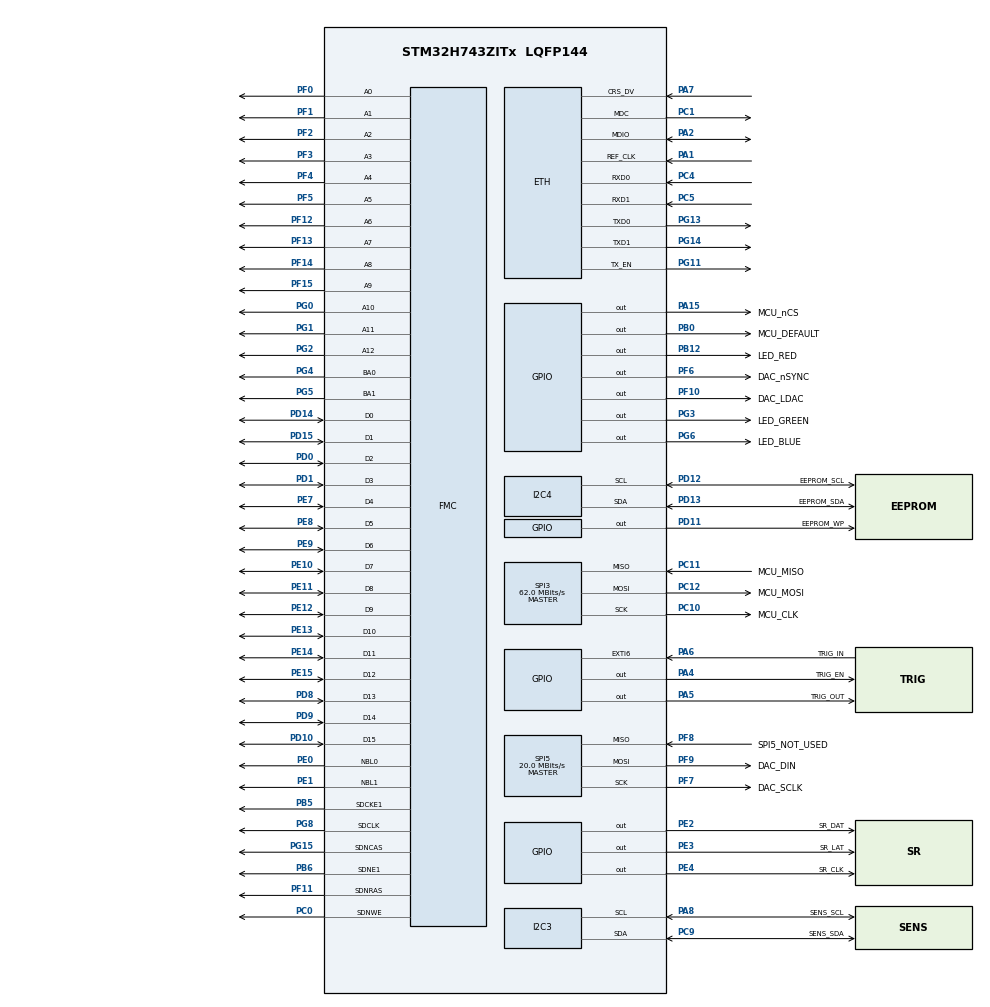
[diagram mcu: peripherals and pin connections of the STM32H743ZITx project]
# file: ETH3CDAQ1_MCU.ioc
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SH.FMC_D7_DA7.0=FMC_D7,sd-16b-d2
FREERTOS.Queues01=QueueTrigger,1,uint8_t,0,Static,QueueTriggerBuffer,QueueTriggerControlBlock
PD12.GPIO_Label=EEPROM_SCL
FMC.RCDDelay2=3
SPI3.Direction=SPI_DIRECTION_2LINES
PG6.PinState=GPIO_PIN_SET
PC10.GPIO_PuPd=GPIO_NOPULL
FMC.SDClockPeriod2=FMC_SDRAM_CLOCK_PERIOD_3
SPI3.VirtualType=VM_MASTER
FMC.SDClockPeriod1=FMC_SDRAM_CLOCK_PERIOD_3
SH.FMC_A0.0=FMC_A0,13b-sda2
PG4.Signal=FMC_A14_BA0
PG8.Signal=FMC_SDCLK
PC12.Signal=SPI3_MOSI
PG6.GPIO_Label=LED_BLUE
PG0.Signal=FMC_A10
CORTEX_M7.TypeExtField-Cortex_Memory_Protection_Unit_Region0_Settings=MPU_TEX_LEVEL1
RCC.PLLFRACN=0
SPI5.DataSize=SPI_DATASIZE_8BIT
FMC.LoadToActiveDelay2=2
PA6.GPIO_Label=TRIG_IN
PA15\ (JTDI).Signal=GPIO_Output
PC5.Mode=RMII
SH.FMC_D5_DA5.0=FMC_D5,sd-16b-d2
PF10.GPIO_PuPd=GPIO_NOPULL
PG13.Signal=ETH_TXD0
PF6.GPIO_Label=DAC_nSYNC
RCC.SYSCLKSource=RCC_SYSCLKSOURCE_PLLCLK
SH.FMC_A15_BA1.0=FMC_BA1,FourSdramBanks2
LWIP.NETMASK_ADDRESS=255.255.255.000
RCC.SPI123CLockSelection=RCC_SPI123CLKSOURCE_PLL2
SH.FMC_D9_DA9.0=FMC_D9,sd-16b-d2
CORTEX_M7.Enable-Cortex_Memory_Protection_Unit_Region0_Settings=MPU_REGION_ENABLE
CORTEX_M7.IsBufferable-Cortex_Memory_Protection_Unit_Region1_Settings=MPU_ACCESS_BUFFERABLE
PF7.Signal=SPI5_SCK
SH.FMC_SDNWE.0=FMC_SDNWE,13b-sda2
I2C4.Timing=0x307075B1
SH.FMC_D11_DA11.0=FMC_D11,sd-16b-d2
PB6.Signal=FMC_SDNE1
PB12.PinState=GPIO_PIN_SET
PB6.Mode=SdramChipSelect2_2
PD0.Signal=FMC_D2_DA2
PD8.Signal=FMC_D13_DA13
PE1.Signal=FMC_NBL1
PF10.GPIO_Label=DAC_LDAC
RCC.DIVM3=4
RCC.DIVM2=4
RCC.DIVM1=4
PB12.GPIO_Label=LED_RED
PG14.Mode=RMII
FMC.SelfRefreshTime2=7
LWIP.MEM_SIZE=16360
PE9.Signal=FMC_D6_DA6
SH.FMC_A2.0=FMC_A2,13b-sda2
PE4.GPIO_Label=SR_CLK
PC9.Mode=I2C
PC11.GPIO_Speed=GPIO_SPEED_FREQ_HIGH
PE2.Signal=GPIO_Output
PF8.Mode=Full_Duplex_Master
PA8.Signal=I2C3_SCL
SH.FMC_D1_DA1.0=FMC_D1,sd-16b-d2
PF3.Signal=FMC_A3
PE10.Signal=FMC_D7_DA7
CORTEX_M7.DisableExec-Cortex_Memory_Protection_Unit_Region1_Settings=MPU_INSTRUCTION_ACCESS_DISABLE
Mcu.Package=LQFP144
NVIC.TimeBase=TIM1_UP_IRQn
SPI3.Mode=SPI_MODE_MASTER
PD12.Signal=I2C4_SCL
NVIC.TimeBaseIP=TIM1
PC11.Mode=Full_Duplex_Master
FMC.WriteRecoveryTime2=4
SH.FMC_A1.0=FMC_A1,13b-sda2
SPI5.CalculateBaudRate=20.0 MBits/s
SH.FMC_SDCLK.0=FMC_SDCLK,13b-sda2
RCC.APB4Freq_Value=120000000
PF14.Signal=FMC_A8
CORTEX_M7.Enable-Cortex_Memory_Protection_Unit_Region1_Settings=MPU_REGION_ENABLE
FREERTOS.configGENERATE_RUN_TIME_STATS=1
FMC.RowCycleDelay2=10
FMC.RowCycleDelay1=10
PH0-OSC_IN\ (PH0).Mode=HSE-External-Oscillator
PA4.GPIO_Label=TRIG_EN
PD15.Signal=FMC_D1_DA1
SH.FMC_D3_DA3.0=FMC_D3,sd-16b-d2
SPI5.VirtualType=VM_MASTER
PC4.Mode=RMII
LWIP.IP_ADDRESS=192.168.000.123
SH.FMC_A4.0=FMC_A4,13b-sda2
RCC.DIVQ1=6
FREERTOS.Tasks01=defaultTask,24,128,StartDefaultTask,Default,NULL,Dynamic,NULL,NULL;LEDTask,8,128,StartTaskLEDStatus,Default,NULL,Dynamic,NULL,NULL;TriggerTask,40,128,StartTriggerTask,Default,NULL,Dynamic,NULL,NULL
LWIP0.BSP.i2caddr=0
PG5.Signal=FMC_A15_BA1
SH.FMC_D10_DA10.0=FMC_D10,sd-16b-d2
PD1.Signal=FMC_D3_DA3
LWIP.LWIP_DHCP=0
PC0.Signal=FMC_SDNWE
LWIP.DEFAULT_THREAD_STACKSIZE=2048
PF8.GPIO_Label=SPI5_NOT_USED
PD10.Signal=FMC_D15_DA15
SH.FMC_A3.0=FMC_A3,13b-sda2
PC10.GPIO_Mode=GPIO_MODE_AF_PP
PA8.GPIO_Label=SENS_SCL
FMC.CASLatency2=FMC_SDRAM_CAS_LATENCY_3
SH.FMC_D15_DA15.0=FMC_D15,sd-16b-d2
RCC.DIVN3=80
RCC.DIVN2=124
RCC.DIVN1=480
CORTEX_M7.BaseAddress-Cortex_Memory_Protection_Unit_Region0_Settings=0x30040000
PA5.Signal=GPIO_Output
PC12.Mode=Full_Duplex_Master
PA15\ (JTDI).GPIO_Speed=GPIO_SPEED_FREQ_VERY_HIGH
PA7.GPIO_Speed=GPIO_SPEED_FREQ_VERY_HIGH
FMC.ReadBurst1=FMC_SDRAM_RBURST_ENABLE
SH.FMC_A6.0=FMC_A6,13b-sda2
FMC.ReadBurst2=FMC_SDRAM_RBURST_ENABLE
PA1.Mode=RMII
PE14.Signal=FMC_D11_DA11
PE15.Signal=FMC_D12_DA12
PE8.Signal=FMC_D5_DA5
RCC.FMCCLockSelection=RCC_FMCCLKSOURCE_PLL
CORTEX_M7.AccessPermission-Cortex_Memory_Protection_Unit_Region0_Settings=MPU_REGION_FULL_ACCESS
PA15\ (JTDI).GPIO_PuPd=GPIO_PULLUP
PF13.Signal=FMC_A7
SH.FMC_SDNCAS.0=FMC_SDNCAS,13b-sda2
PA4.Signal=GPIO_Output
PB5.Signal=FMC_SDCKE1
ETH.MediaInterface=HAL_ETH_RMII_MODE
RCC.Spi45ClockSelection=RCC_SPI45CLKSOURCE_PLL3
PD12.Mode=I2C
PA5.GPIO_Label=TRIG_OUT
PE3.GPIO_Speed=GPIO_SPEED_FREQ_HIGH
PD11.Signal=GPIO_Output
PC12.GPIO_Label=MCU_MOSI
SH.FMC_A5.0=FMC_A5,13b-sda2
PG11.Mode=RMII
ProjectManager.HeapSize=0x200
LWIP.Version=v2.1.2_Cube
PF9.Signal=SPI5_MOSI
NVIC.PriorityGroup=NVIC_PRIORITYGROUP_4
PC5.GPIO_Speed=GPIO_SPEED_FREQ_VERY_HIGH
PF6.GPIO_PuPd=GPIO_PULLUP
PE3.Signal=GPIO_Output
PA8.Mode=I2C
PA15\ (JTDI).PinState=GPIO_PIN_SET
PF4.Signal=FMC_A4
PG3.GPIO_Label=LED_GREEN
PF10.PinState=GPIO_PIN_RESET
PB0.Signal=GPIO_Output
PC1.Signal=ETH_MDC
PC1.Mode=RMII
PF6.GPIO_Speed=GPIO_SPEED_FREQ_HIGH
Mcu.Family=STM32H7
LWIP0.BSP.STBoard=false
SH.FMC_A8.0=FMC_A8,13b-sda2
RCC.CortexFreq_Value=480000000
PG6.Signal=GPIO_Output
RCC.HPRE=RCC_HCLK_DIV2
SH.FMC_D14_DA14.0=FMC_D14,sd-16b-d2
PG2.Signal=FMC_A12
PH0-OSC_IN\ (PH0).Signal=RCC_OSC_IN
PC10.Signal=SPI3_SCK
SH.FMC_NBL0.0=FMC_NBL0,Sd2ByteEnable2
PA2.GPIO_Speed=GPIO_SPEED_FREQ_VERY_HIGH
PE2.GPIO_Speed=GPIO_SPEED_FREQ_HIGH
SH.FMC_D6_DA6.0=FMC_D6,sd-16b-d2
PF9.GPIO_Speed=GPIO_SPEED_FREQ_HIGH
PB0.GPIO_Label=MCU_DEFAULT
PC10.GPIO_Speed=GPIO_SPEED_FREQ_HIGH
NVIC.TIM1_UP_IRQn=true\:0\:0\:false\:false\:true\:false\:false\:true
SH.FMC_A14_BA0.0=FMC_BA0,FourSdramBanks2
SH.FMC_A11.0=FMC_A11,13b-sda2
PG11.Signal=ETH_TX_EN
PG15.Signal=FMC_SDNCAS
ProjectManager.StackSize=0x400
VP_FREERTOS_VS_CMSIS_V2.Mode=CMSIS_V2
PD13.Signal=I2C4_SDA
SH.FMC_A7.0=FMC_A7,13b-sda2
PF6.PinState=GPIO_PIN_SET
PD11.GPIO_Label=EEPROM_WP
FMC.BankMapConfig=FMC_SWAPBMAP_DISABLE
RCC.HCLKFreq_Value=240000000
SH.FMC_NBL1.0=FMC_NBL1,Sd2ByteEnable2
PF12.Signal=FMC_A6
SPI5.CLKPolarity=SPI_POLARITY_HIGH
SH.FMC_A10.0=FMC_A10,13b-sda2
SPI3.DataSize=SPI_DATASIZE_8BIT
NVIC.ETH_IRQn=true\:5\:0\:true\:false\:true\:true\:true\:true
PH1-OSC_OUT\ (PH1).Mode=HSE-External-Oscillator
RCC.HSE_VALUE=8000000
SH.FMC_D8_DA8.0=FMC_D8,sd-16b-d2
FMC.RPDelay2=3
FMC.RPDelay1=3
FMC.ExitSelfRefreshDelay2=11
PA4.GPIO_Speed=GPIO_SPEED_FREQ_MEDIUM
SH.FMC_D2_DA2.0=FMC_D2,sd-16b-d2
PG11.GPIO_Speed=GPIO_SPEED_FREQ_VERY_HIGH
PC4.GPIO_Speed=GPIO_SPEED_FREQ_VERY_HIGH
PF9.Mode=Full_Duplex_Master
PE13.Signal=FMC_D10_DA10
PF7.GPIO_Speed=GPIO_SPEED_FREQ_HIGH
PF7.GPIO_Label=DAC_SCLK
PE4.GPIO_Speed=GPIO_SPEED_FREQ_HIGH
VP_SYS_VS_tim1.Mode=TIM1
PF11.Signal=FMC_SDNRAS
PC11.GPIO_Label=MCU_MISO
PB5.Mode=SdramChipSelect2_2
PG13.Mode=RMII
SH.FMC_SDNRAS.0=FMC_SDNRAS,13b-sda2
LWIP0.BSP.solution=LAN8742
PE4.Signal=GPIO_Output
CORTEX_M7.DisableExec-Cortex_Memory_Protection_Unit_Region0_Settings=MPU_INSTRUCTION_ACCESS_DISABLE
RCC.APB3Freq_Value=120000000
LWIP0.BSP.component=LAN8742
PD13.GPIO_Label=EEPROM_SDA
SPI5.BaudRatePrescaler=SPI_BAUDRATEPRESCALER_4
PA6.Signal=GPXTI6
SH.FMC_D0_DA0.0=FMC_D0,sd-16b-d2
RCC.D1PPRE=RCC_APB3_DIV2
CORTEX_M7.BaseAddress-Cortex_Memory_Protection_Unit_Region1_Settings=0x30040000
SH.FMC_A9.0=FMC_A9,13b-sda2
PF8.Signal=SPI5_MISO
SH.FMC_D4_DA4.0=FMC_D4,sd-16b-d2
PF5.Signal=FMC_A5
CORTEX_M7.Size-Cortex_Memory_Protection_Unit_Region1_Settings=MPU_REGION_SIZE_256B
I2C3.Timing=0x307075B1
PG13.GPIO_Speed=GPIO_SPEED_FREQ_VERY_HIGH
PF0.Signal=FMC_A0
PC5.Signal=ETH_RXD1
PE7.Signal=FMC_D4_DA4
CORTEX_M7.IsShareable-Cortex_Memory_Protection_Unit_Region1_Settings=MPU_ACCESS_SHAREABLE
PE2.GPIO_Label=SR_DAT
SH.FMC_A12.0=FMC_A12,13b-sda2
RCC.PLLSourceVirtual=RCC_PLLSOURCE_HSE
CORTEX_M7.CPU_ICache=Enabled
PA7.Mode=RMII
PC10.GPIO_Label=MCU_CLK
PC9.GPIO_Label=SENS_SDA
PG3.Signal=GPIO_Output
PG1.Signal=FMC_A11
PC11.Signal=SPI3_MISO
PF10.GPIO_Speed=GPIO_SPEED_FREQ_HIGH
PC4.Signal=ETH_RXD0
PC10.Mode=Full_Duplex_Master
LWIP.LWIP_IPV6=0
RCC.D2PPRE2=RCC_APB2_DIV2
RCC.D2PPRE1=RCC_APB1_DIV2
PD9.Signal=FMC_D14_DA14
SPI5.Mode=SPI_MODE_MASTER
PH1-OSC_OUT\ (PH1).Signal=RCC_OSC_OUT
VP_LWIP_VS_Enabled.Mode=Enabled
LWIP.GATEWAY_ADDRESS=192.168.000.001
PB0.GPIO_Speed=GPIO_SPEED_FREQ_HIGH
PF7.Mode=Full_Duplex_Master
CORTEX_M7.MPU_Control=MPU_PRIVILEGED_DEFAULT
PA4.PinState=GPIO_PIN_SET
PF6.Signal=GPIO_Output
ProjectManager.TargetToolchain=STM32CubeIDE
SH.FMC_D13_DA13.0=FMC_D13,sd-16b-d2
LWIP.TCPIP_THREAD_STACKSIZE=2048
PD13.Mode=I2C
PF2.Signal=FMC_A2
LWIP0.BSP.instance=LAN8742
RCC.USBFreq_Value=160000000
PF9.GPIO_Label=DAC_DIN
PE11.Signal=FMC_D8_DA8
LWIP0.BSP.api=BSP_COMPONENT_DRIVER
PA1.Signal=ETH_REF_CLK
PG14.Signal=ETH_TXD1
board=custom
PG3.PinState=GPIO_PIN_SET
RCC.APB2Freq_Value=120000000
SPI3.CalculateBaudRate=62.0 MBits/s
PF10.Signal=GPIO_Output
PA1.GPIO_Speed=GPIO_SPEED_FREQ_VERY_HIGH
RCC.ADCFreq_Value=124000000
SPI3.BaudRatePrescaler=SPI_BAUDRATEPRESCALER_2
SH.FMC_D12_DA12.0=FMC_D12,sd-16b-d2
PF15.Signal=FMC_A9
PF1.Signal=FMC_A1
PA15\ (JTDI).GPIO_Label=MCU_nCS
Mcu.Name=STM32H743ZITx
PE0.Signal=FMC_NBL0
CORTEX_M7.Size-Cortex_Memory_Protection_Unit_Region0_Settings=MPU_REGION_SIZE_32KB
PE12.Signal=FMC_D9_DA9
PA2.Signal=ETH_MDIO
CORTEX_M7.AccessPermission-Cortex_Memory_Protection_Unit_Region1_Settings=MPU_REGION_FULL_ACCESS
PD14.Signal=FMC_D0_DA0
RCC.SYSCLKFreq_VALUE=480000000
LWIP.BSP.number=1
NVIC.EXTI9_5_IRQn=true\:9\:0\:true\:false\:true\:true\:true\:true
PA5.GPIO_Speed=GPIO_SPEED_FREQ_MEDIUM
PA2.Mode=RMII
PE3.GPIO_Label=SR_LAT
RCC.D3PPRE=RCC_APB4_DIV2
PC9.Signal=I2C3_SDA
CORTEX_M7.CPU_DCache=Enabled
LWIP0.BSP.name=Driver_PHY
RCC.APB1Freq_Value=120000000
PC12.GPIO_Speed=GPIO_SPEED_FREQ_HIGH
PG14.GPIO_Speed=GPIO_SPEED_FREQ_VERY_HIGH
PB12.Signal=GPIO_Output
SPI5.Direction=SPI_DIRECTION_2LINES
PA7.Signal=ETH_CRS_DV

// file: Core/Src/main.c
/* USER CODE BEGIN Header */
/**
  ******************************************************************************
  * @file           : main.c
  * @brief          : Main program body
  ******************************************************************************
  * @attention
  *
  * <h2><center>&copy; Copyright (c) 2020 STMicroelectronics.
  * All rights reserved.</center></h2>
  *
  * This software component is licensed by ST under BSD 3-Clause license,
  * the "License"; You may not use this file except in compliance with the
  * License. You may obtain a copy of the License at:
  *                        opensource.org/licenses/BSD-3-Clause
  *
  ******************************************************************************
  */
/* USER CODE END Header */
#include "main.h"
#include "cmsis_os.h"
#include "lwip.h"

/* USER CODE BEGIN Includes */
#include "bsp.h"
#include "led.h"
#include "dwt_delay.h"
#include "DG211.h"
#include "ADS8681.h"
#include "DG211.h"
#include "DAC8564.h"
#include "measure.h"
#include "sdram.h"
#include "module.h"
#include "scpi_server.h"
/* USER CODE END Includes */

typedef StaticQueue_t osStaticMessageQDef_t;

I2C_HandleTypeDef hi2c3;
I2C_HandleTypeDef hi2c4;

SPI_HandleTypeDef hspi3;
SPI_HandleTypeDef hspi5;

SDRAM_HandleTypeDef hsdram2;

/* Definitions for defaultTask */
osThreadId_t defaultTaskHandle;
const osThreadAttr_t defaultTask_attributes = {
  .name = "defaultTask",
  .stack_size = 128 * 4,
  .priority = (osPriority_t) osPriorityNormal,
};
/* Definitions for LEDTask */
osThreadId_t LEDTaskHandle;
const osThreadAttr_t LEDTask_attributes = {
  .name = "LEDTask",
  .stack_size = 128 * 4,
  .priority = (osPriority_t) osPriorityLow,
};
/* Definitions for TriggerTask */
osThreadId_t TriggerTaskHandle;
const osThreadAttr_t TriggerTask_attributes = {
  .name = "TriggerTask",
  .stack_size = 128 * 4,
  .priority = (osPriority_t) osPriorityHigh,
};
/* Definitions for QueueTrigger */
osMessageQueueId_t QueueTriggerHandle;
uint8_t QueueTriggerBuffer[ 1 * sizeof( uint8_t ) ];
osStaticMessageQDef_t QueueTriggerControlBlock;
const osMessageQueueAttr_t QueueTrigger_attributes = {
  .name = "QueueTrigger",
  .cb_mem = &QueueTriggerControlBlock,
  .cb_size = sizeof(QueueTriggerControlBlock),
  .mq_mem = &QueueTriggerBuffer,
  .mq_size = sizeof(QueueTriggerBuffer)
};
/* USER CODE BEGIN PV */

FMC_SDRAM_CommandTypeDef command;
osMessageQueueId_t LEDMessageQueue;

/* USER CODE END PV */

void SystemClock_Config(void);
static void MPU_Config(void);
static void MX_GPIO_Init(void);
static void MX_FMC_Init(void);
static void MX_I2C3_Init(void);
static void MX_I2C4_Init(void);
static void MX_SPI3_Init(void);
static void MX_SPI5_Init(void);
void StartDefaultTask(void *argument);
void StartTaskLEDStatus(void *argument);
void StartTriggerTask(void *argument);

int main(void)
{

  /* MPU Configuration--------------------------------------------------------*/
  MPU_Config();

  /* Enable I-Cache---------------------------------------------------------*/
  SCB_EnableICache();

  /* Enable D-Cache---------------------------------------------------------*/
  SCB_EnableDCache();

  /* MCU Configuration--------------------------------------------------------*/

  /* Reset of all peripherals, Initializes the Flash interface and the Systick. */
  HAL_Init();

  /* Configure the system clock */
  SystemClock_Config();

  /* Initialize all configured peripherals */
  MX_GPIO_Init();
  MX_FMC_Init();
  MX_I2C3_Init();
  MX_I2C4_Init();
  MX_SPI3_Init();
  MX_SPI5_Init();
  /* USER CODE BEGIN 2 */
  HAL_Delay(100);
  BSP_Init();
  MX_LWIP_Init();
  SDRAM_Init(&hsdram2, &command);
  DWT_Init();
  DG211_Init();
  DAC8564_Init();
  ADS8681_Init();
  MODULE_Init();
  MEAS_ZeroOffset();
  /* USER CODE END 2 */

  /* Init scheduler */
  osKernelInitialize();

  /* Create the queue(s) */
  /* creation of QueueTrigger */
  QueueTriggerHandle = osMessageQueueNew (1, sizeof(uint8_t), &QueueTrigger_attributes);

  /* Create the thread(s) */
  /* creation of defaultTask */
 // defaultTaskHandle = osThreadNew(StartDefaultTask, NULL, &defaultTask_attributes);

  /* creation of LEDTask */
  LEDTaskHandle = osThreadNew(StartTaskLEDStatus, NULL, &LEDTask_attributes);

  /* creation of TriggerTask */
  TriggerTaskHandle = osThreadNew(StartTriggerTask, NULL, &TriggerTask_attributes);

  /* USER CODE BEGIN RTOS_THREADS */
  scpi_server_init();
  /* USER CODE END RTOS_THREADS */

  /* Start scheduler */
  osKernelStart();

  /* We should never get here as control is now taken by the scheduler */
  /* Infinite loop */
  while (1)
  {

  }
}

void SystemClock_Config(void)
{
  RCC_OscInitTypeDef RCC_OscInitStruct = {0};
  RCC_ClkInitTypeDef RCC_ClkInitStruct = {0};

  /** Supply configuration update enable
  */
  HAL_PWREx_ConfigSupply(PWR_LDO_SUPPLY);
  /** Configure the main internal regulator output voltage
  */
  __HAL_PWR_VOLTAGESCALING_CONFIG(PWR_REGULATOR_VOLTAGE_SCALE0);

  while(!__HAL_PWR_GET_FLAG(PWR_FLAG_VOSRDY)) {}
  /** Macro to configure the PLL clock source
  */
  __HAL_RCC_PLL_PLLSOURCE_CONFIG(RCC_PLLSOURCE_HSE);
  /** Initializes the RCC Oscillators according to the specified parameters
  * in the RCC_OscInitTypeDef structure.
  */
  RCC_OscInitStruct.OscillatorType = RCC_OSCILLATORTYPE_HSE;
  RCC_OscInitStruct.HSEState = RCC_HSE_ON;
  RCC_OscInitStruct.PLL.PLLState = RCC_PLL_ON;
  RCC_OscInitStruct.PLL.PLLSource = RCC_PLLSOURCE_HSE;
  RCC_OscInitStruct.PLL.PLLM = 4;
  RCC_OscInitStruct.PLL.PLLN = 480;
  RCC_OscInitStruct.PLL.PLLP = 2;
  RCC_OscInitStruct.PLL.PLLQ = 6;
  RCC_OscInitStruct.PLL.PLLR = 2;
  RCC_OscInitStruct.PLL.PLLRGE = RCC_PLL1VCIRANGE_1;
  RCC_OscInitStruct.PLL.PLLVCOSEL = RCC_PLL1VCOWIDE;
  RCC_OscInitStruct.PLL.PLLFRACN = 0;
  if (HAL_RCC_OscConfig(&RCC_OscInitStruct) != HAL_OK)
  {
    Error_Handler();
  }
  /** Initializes the CPU, AHB and APB buses clocks
  */
  RCC_ClkInitStruct.ClockType = RCC_CLOCKTYPE_HCLK|RCC_CLOCKTYPE_SYSCLK
                              |RCC_CLOCKTYPE_PCLK1|RCC_CLOCKTYPE_PCLK2
                              |RCC_CLOCKTYPE_D3PCLK1|RCC_CLOCKTYPE_D1PCLK1;
  RCC_ClkInitStruct.SYSCLKSource = RCC_SYSCLKSOURCE_PLLCLK;
  RCC_ClkInitStruct.SYSCLKDivider = RCC_SYSCLK_DIV1;
  RCC_ClkInitStruct.AHBCLKDivider = RCC_HCLK_DIV2;
  RCC_ClkInitStruct.APB3CLKDivider = RCC_APB3_DIV2;
  RCC_ClkInitStruct.APB1CLKDivider = RCC_APB1_DIV2;
  RCC_ClkInitStruct.APB2CLKDivider = RCC_APB2_DIV2;
  RCC_ClkInitStruct.APB4CLKDivider = RCC_APB4_DIV2;

  if (HAL_RCC_ClockConfig(&RCC_ClkInitStruct, FLASH_LATENCY_4) != HAL_OK)
  {
    Error_Handler();
  }
}

static void MX_I2C3_Init(void)
{

  hi2c3.Instance = I2C3;
  hi2c3.Init.Timing = 0x307075B1;
  hi2c3.Init.OwnAddress1 = 0;
  hi2c3.Init.AddressingMode = I2C_ADDRESSINGMODE_7BIT;
  hi2c3.Init.DualAddressMode = I2C_DUALADDRESS_DISABLE;
  hi2c3.Init.OwnAddress2 = 0;
  hi2c3.Init.OwnAddress2Masks = I2C_OA2_NOMASK;
  hi2c3.Init.GeneralCallMode = I2C_GENERALCALL_DISABLE;
  hi2c3.Init.NoStretchMode = I2C_NOSTRETCH_DISABLE;
  if (HAL_I2C_Init(&hi2c3) != HAL_OK)
  {
    Error_Handler();
  }
  /** Configure Analogue filter
  */
  if (HAL_I2CEx_ConfigAnalogFilter(&hi2c3, I2C_ANALOGFILTER_ENABLE) != HAL_OK)
  {
    Error_Handler();
  }
  /** Configure Digital filter
  */
  if (HAL_I2CEx_ConfigDigitalFilter(&hi2c3, 0) != HAL_OK)
  {
    Error_Handler();
  }

}

static void MX_I2C4_Init(void)
{

  hi2c4.Instance = I2C4;
  hi2c4.Init.Timing = 0x307075B1;
  hi2c4.Init.OwnAddress1 = 0;
  hi2c4.Init.AddressingMode = I2C_ADDRESSINGMODE_7BIT;
  hi2c4.Init.DualAddressMode = I2C_DUALADDRESS_DISABLE;
  hi2c4.Init.OwnAddress2 = 0;
  hi2c4.Init.OwnAddress2Masks = I2C_OA2_NOMASK;
  hi2c4.Init.GeneralCallMode = I2C_GENERALCALL_DISABLE;
  hi2c4.Init.NoStretchMode = I2C_NOSTRETCH_DISABLE;
  if (HAL_I2C_Init(&hi2c4) != HAL_OK)
  {
    Error_Handler();
  }
  /** Configure Analogue filter
  */
  if (HAL_I2CEx_ConfigAnalogFilter(&hi2c4, I2C_ANALOGFILTER_ENABLE) != HAL_OK)
  {
    Error_Handler();
  }
  /** Configure Digital filter
  */
  if (HAL_I2CEx_ConfigDigitalFilter(&hi2c4, 0) != HAL_OK)
  {
    Error_Handler();
  }

}

static void MX_SPI3_Init(void)
{

  /* SPI3 parameter configuration*/
  hspi3.Instance = SPI3;
  hspi3.Init.Mode = SPI_MODE_MASTER;
  hspi3.Init.Direction = SPI_DIRECTION_2LINES;
  hspi3.Init.DataSize = SPI_DATASIZE_32BIT;
  hspi3.Init.CLKPolarity = SPI_POLARITY_LOW;
  hspi3.Init.CLKPhase = SPI_PHASE_1EDGE;
  hspi3.Init.NSS = SPI_NSS_SOFT;
  hspi3.Init.BaudRatePrescaler = SPI_BAUDRATEPRESCALER_2;
  hspi3.Init.FirstBit = SPI_FIRSTBIT_MSB;
  hspi3.Init.TIMode = SPI_TIMODE_DISABLE;
  hspi3.Init.CRCCalculation = SPI_CRCCALCULATION_DISABLE;
  hspi3.Init.CRCPolynomial = 0x0;
  hspi3.Init.NSSPMode = SPI_NSS_PULSE_ENABLE;
  hspi3.Init.NSSPolarity = SPI_NSS_POLARITY_LOW;
  hspi3.Init.FifoThreshold = SPI_FIFO_THRESHOLD_01DATA;
  hspi3.Init.TxCRCInitializationPattern = SPI_CRC_INITIALIZATION_ALL_ZERO_PATTERN;
  hspi3.Init.RxCRCInitializationPattern = SPI_CRC_INITIALIZATION_ALL_ZERO_PATTERN;
  hspi3.Init.MasterSSIdleness = SPI_MASTER_SS_IDLENESS_00CYCLE;
  hspi3.Init.MasterInterDataIdleness = SPI_MASTER_INTERDATA_IDLENESS_00CYCLE;
  hspi3.Init.MasterReceiverAutoSusp = SPI_MASTER_RX_AUTOSUSP_DISABLE;
  hspi3.Init.MasterKeepIOState = SPI_MASTER_KEEP_IO_STATE_DISABLE;
  hspi3.Init.IOSwap = SPI_IO_SWAP_DISABLE;
  if (HAL_SPI_Init(&hspi3) != HAL_OK)
  {
    Error_Handler();
  }

}

static void MX_SPI5_Init(void)
{

  /* SPI5 parameter configuration*/
  hspi5.Instance = SPI5;
  hspi5.Init.Mode = SPI_MODE_MASTER;
  hspi5.Init.Direction = SPI_DIRECTION_2LINES;
  hspi5.Init.DataSize = SPI_DATASIZE_8BIT;
  hspi5.Init.CLKPolarity = SPI_POLARITY_HIGH;
  hspi5.Init.CLKPhase = SPI_PHASE_1EDGE;
  hspi5.Init.NSS = SPI_NSS_SOFT;
  hspi5.Init.BaudRatePrescaler = SPI_BAUDRATEPRESCALER_4;
  hspi5.Init.FirstBit = SPI_FIRSTBIT_MSB;
  hspi5.Init.TIMode = SPI_TIMODE_DISABLE;
  hspi5.Init.CRCCalculation = SPI_CRCCALCULATION_DISABLE;
  hspi5.Init.CRCPolynomial = 0x0;
  hspi5.Init.NSSPMode = SPI_NSS_PULSE_ENABLE;
  hspi5.Init.NSSPolarity = SPI_NSS_POLARITY_LOW;
  hspi5.Init.FifoThreshold = SPI_FIFO_THRESHOLD_01DATA;
  hspi5.Init.TxCRCInitializationPattern = SPI_CRC_INITIALIZATION_ALL_ZERO_PATTERN;
  hspi5.Init.RxCRCInitializationPattern = SPI_CRC_INITIALIZATION_ALL_ZERO_PATTERN;
  hspi5.Init.MasterSSIdleness = SPI_MASTER_SS_IDLENESS_00CYCLE;
  hspi5.Init.MasterInterDataIdleness = SPI_MASTER_INTERDATA_IDLENESS_00CYCLE;
  hspi5.Init.MasterReceiverAutoSusp = SPI_MASTER_RX_AUTOSUSP_DISABLE;
  hspi5.Init.MasterKeepIOState = SPI_MASTER_KEEP_IO_STATE_DISABLE;
  hspi5.Init.IOSwap = SPI_IO_SWAP_DISABLE;
  if (HAL_SPI_Init(&hspi5) != HAL_OK)
  {
    Error_Handler();
  }

}

/* FMC initialization function */
static void MX_FMC_Init(void)
{

  FMC_SDRAM_TimingTypeDef SdramTiming = {0};

  /** Perform the SDRAM2 memory initialization sequence
  */
  hsdram2.Instance = FMC_SDRAM_DEVICE;
  /* hsdram2.Init */
  hsdram2.Init.SDBank = FMC_SDRAM_BANK2;
  hsdram2.Init.ColumnBitsNumber = FMC_SDRAM_COLUMN_BITS_NUM_8;
  hsdram2.Init.RowBitsNumber = FMC_SDRAM_ROW_BITS_NUM_13;
  hsdram2.Init.MemoryDataWidth = FMC_SDRAM_MEM_BUS_WIDTH_16;
  hsdram2.Init.InternalBankNumber = FMC_SDRAM_INTERN_BANKS_NUM_4;
  hsdram2.Init.CASLatency = FMC_SDRAM_CAS_LATENCY_3;
  hsdram2.Init.WriteProtection = FMC_SDRAM_WRITE_PROTECTION_DISABLE;
  hsdram2.Init.SDClockPeriod = FMC_SDRAM_CLOCK_PERIOD_3;
  hsdram2.Init.ReadBurst = FMC_SDRAM_RBURST_ENABLE;
  hsdram2.Init.ReadPipeDelay = FMC_SDRAM_RPIPE_DELAY_0;
  /* SdramTiming */
  SdramTiming.LoadToActiveDelay = 2;
  SdramTiming.ExitSelfRefreshDelay = 11;
  SdramTiming.SelfRefreshTime = 7;
  SdramTiming.RowCycleDelay = 10;
  SdramTiming.WriteRecoveryTime = 4;
  SdramTiming.RPDelay = 3;
  SdramTiming.RCDDelay = 3;

  if (HAL_SDRAM_Init(&hsdram2, &SdramTiming) != HAL_OK)
  {
    Error_Handler( );
  }

}

static void MX_GPIO_Init(void)
{
  LL_EXTI_InitTypeDef EXTI_InitStruct = {0};
  LL_GPIO_InitTypeDef GPIO_InitStruct = {0};

  /* GPIO Ports Clock Enable */
  LL_AHB4_GRP1_EnableClock(LL_AHB4_GRP1_PERIPH_GPIOE);
  LL_AHB4_GRP1_EnableClock(LL_AHB4_GRP1_PERIPH_GPIOF);
  LL_AHB4_GRP1_EnableClock(LL_AHB4_GRP1_PERIPH_GPIOH);
  LL_AHB4_GRP1_EnableClock(LL_AHB4_GRP1_PERIPH_GPIOC);
  LL_AHB4_GRP1_EnableClock(LL_AHB4_GRP1_PERIPH_GPIOA);
  LL_AHB4_GRP1_EnableClock(LL_AHB4_GRP1_PERIPH_GPIOB);
  LL_AHB4_GRP1_EnableClock(LL_AHB4_GRP1_PERIPH_GPIOG);
  LL_AHB4_GRP1_EnableClock(LL_AHB4_GRP1_PERIPH_GPIOD);

  /**/
  LL_GPIO_ResetOutputPin(GPIOE, SR_DAT_Pin|SR_LAT_Pin|SR_CLK_Pin);

  /**/
  LL_GPIO_ResetOutputPin(DAC_LDAC_GPIO_Port, DAC_LDAC_Pin);

  /**/
  LL_GPIO_ResetOutputPin(TRIG_OUT_GPIO_Port, TRIG_OUT_Pin);

  /**/
  LL_GPIO_ResetOutputPin(EEPROM_WP_GPIO_Port, EEPROM_WP_Pin);

  /**/
  LL_GPIO_SetOutputPin(DAC_nSYNC_GPIO_Port, DAC_nSYNC_Pin);

  /**/
  LL_GPIO_SetOutputPin(GPIOA, TRIG_EN_Pin|MCU_nCS_Pin);

  /**/
  LL_GPIO_SetOutputPin(LED_RED_GPIO_Port, LED_RED_Pin);

  /**/
  LL_GPIO_SetOutputPin(GPIOG, LED_GREEN_Pin|LED_BLUE_Pin);

  /**/
  GPIO_InitStruct.Pin = SR_DAT_Pin|SR_LAT_Pin|SR_CLK_Pin;
  GPIO_InitStruct.Mode = LL_GPIO_MODE_OUTPUT;
  GPIO_InitStruct.Speed = LL_GPIO_SPEED_FREQ_HIGH;
  GPIO_InitStruct.OutputType = LL_GPIO_OUTPUT_PUSHPULL;
  GPIO_InitStruct.Pull = LL_GPIO_PULL_NO;
  LL_GPIO_Init(GPIOE, &GPIO_InitStruct);

  /**/
  GPIO_InitStruct.Pin = DAC_nSYNC_Pin;
  GPIO_InitStruct.Mode = LL_GPIO_MODE_OUTPUT;
  GPIO_InitStruct.Speed = LL_GPIO_SPEED_FREQ_HIGH;
  GPIO_InitStruct.OutputType = LL_GPIO_OUTPUT_PUSHPULL;
  GPIO_InitStruct.Pull = LL_GPIO_PULL_UP;
  LL_GPIO_Init(DAC_nSYNC_GPIO_Port, &GPIO_InitStruct);

  /**/
  GPIO_InitStruct.Pin = DAC_LDAC_Pin;
  GPIO_InitStruct.Mode = LL_GPIO_MODE_OUTPUT;
  GPIO_InitStruct.Speed = LL_GPIO_SPEED_FREQ_HIGH;
  GPIO_InitStruct.OutputType = LL_GPIO_OUTPUT_PUSHPULL;
  GPIO_InitStruct.Pull = LL_GPIO_PULL_NO;
  LL_GPIO_Init(DAC_LDAC_GPIO_Port, &GPIO_InitStruct);

  /**/
  GPIO_InitStruct.Pin = TRIG_EN_Pin|TRIG_OUT_Pin;
  GPIO_InitStruct.Mode = LL_GPIO_MODE_OUTPUT;
  GPIO_InitStruct.Speed = LL_GPIO_SPEED_FREQ_MEDIUM;
  GPIO_InitStruct.OutputType = LL_GPIO_OUTPUT_PUSHPULL;
  GPIO_InitStruct.Pull = LL_GPIO_PULL_NO;
  LL_GPIO_Init(GPIOA, &GPIO_InitStruct);

  /**/
  GPIO_InitStruct.Pin = MCU_DEFAULT_Pin;
  GPIO_InitStruct.Mode = LL_GPIO_MODE_INPUT;
  GPIO_InitStruct.Pull = LL_GPIO_PULL_NO;
  LL_GPIO_Init(MCU_DEFAULT_GPIO_Port, &GPIO_InitStruct);

  /**/
  GPIO_InitStruct.Pin = LED_RED_Pin;
  GPIO_InitStruct.Mode = LL_GPIO_MODE_OUTPUT;
  GPIO_InitStruct.Speed = LL_GPIO_SPEED_FREQ_LOW;
  GPIO_InitStruct.OutputType = LL_GPIO_OUTPUT_PUSHPULL;
  GPIO_InitStruct.Pull = LL_GPIO_PULL_NO;
  LL_GPIO_Init(LED_RED_GPIO_Port, &GPIO_InitStruct);

  /**/
  GPIO_InitStruct.Pin = EEPROM_WP_Pin;
  GPIO_InitStruct.Mode = LL_GPIO_MODE_OUTPUT;
  GPIO_InitStruct.Speed = LL_GPIO_SPEED_FREQ_LOW;
  GPIO_InitStruct.OutputType = LL_GPIO_OUTPUT_PUSHPULL;
  GPIO_InitStruct.Pull = LL_GPIO_PULL_NO;
  LL_GPIO_Init(EEPROM_WP_GPIO_Port, &GPIO_InitStruct);

  /**/
  GPIO_InitStruct.Pin = LED_GREEN_Pin|LED_BLUE_Pin;
  GPIO_InitStruct.Mode = LL_GPIO_MODE_OUTPUT;
  GPIO_InitStruct.Speed = LL_GPIO_SPEED_FREQ_LOW;
  GPIO_InitStruct.OutputType = LL_GPIO_OUTPUT_PUSHPULL;
  GPIO_InitStruct.Pull = LL_GPIO_PULL_NO;
  LL_GPIO_Init(GPIOG, &GPIO_InitStruct);

  /**/
  GPIO_InitStruct.Pin = MCU_nCS_Pin;
  GPIO_InitStruct.Mode = LL_GPIO_MODE_OUTPUT;
  GPIO_InitStruct.Speed = LL_GPIO_SPEED_FREQ_VERY_HIGH;
  GPIO_InitStruct.OutputType = LL_GPIO_OUTPUT_PUSHPULL;
  GPIO_InitStruct.Pull = LL_GPIO_PULL_UP;
  LL_GPIO_Init(MCU_nCS_GPIO_Port, &GPIO_InitStruct);

  /**/
  LL_SYSCFG_SetEXTISource(LL_SYSCFG_EXTI_PORTA, LL_SYSCFG_EXTI_LINE6);

  /**/
  EXTI_InitStruct.Line_0_31 = LL_EXTI_LINE_6;
  EXTI_InitStruct.Line_32_63 = LL_EXTI_LINE_NONE;
  EXTI_InitStruct.Line_64_95 = LL_EXTI_LINE_NONE;
  EXTI_InitStruct.LineCommand = ENABLE;
  EXTI_InitStruct.Mode = LL_EXTI_MODE_IT;
  EXTI_InitStruct.Trigger = LL_EXTI_TRIGGER_RISING;
  LL_EXTI_Init(&EXTI_InitStruct);

  /**/
  LL_GPIO_SetPinPull(TRIG_IN_GPIO_Port, TRIG_IN_Pin, LL_GPIO_PULL_NO);

  /* EXTI interrupt init*/
  NVIC_SetPriority(EXTI9_5_IRQn, NVIC_EncodePriority(NVIC_GetPriorityGrouping(),9, 0));
  NVIC_EnableIRQ(EXTI9_5_IRQn);

}

void StartDefaultTask(void *argument)
{
  /* init code for LWIP */
  MX_LWIP_Init();
  /* USER CODE BEGIN 5 */

  /* Infinite loop */
  for (;;) {
    osDelay(1000);

  }
  /* USER CODE END 5 */
}

void StartTaskLEDStatus(void *argument)
{
  /* USER CODE BEGIN StartTaskLEDStatus */

	uint8_t led_color, tmp;
	osStatus_t status;

	led_color = 0;
	tmp = 0;

  /* Infinite loop */
  for(;;)
  {
	  status = osMessageQueueGet(LEDMessageQueue, &led_color, NULL, 0U);

	  if(osOK == status)
	  {
		  tmp = led_color;
	  }
	  else
	  {
		  led_color = tmp;
	  }
	  switch(led_color)
	  {
	  	  case RED: LL_GPIO_TogglePin(LED_RED_GPIO_Port, LED_RED_Pin); break;
	  	  case GREEN: LL_GPIO_TogglePin(LED_GREEN_GPIO_Port, LED_GREEN_Pin); break;
	  	  case BLUE: LL_GPIO_TogglePin(LED_BLUE_GPIO_Port, LED_BLUE_Pin); break;
	  	  default: LL_GPIO_TogglePin(LED_RED_GPIO_Port, LED_RED_Pin); break;
	  }

	  osDelay(pdMS_TO_TICKS(500));
  }
  /* USER CODE END StartTaskLEDStatus */
}

void StartTriggerTask(void *argument)
{
  /* USER CODE BEGIN StartTriggerTask */
		uint8_t trigger_status = 0;
	  /* Infinite loop */

	  for(;;)
	  {
		  if(osOK == osMessageQueueGet(QueueTriggerHandle, &trigger_status, NULL, 10U))
		  {
				LL_GPIO_TogglePin(LED_RED_GPIO_Port, LED_RED_Pin);
		  }
		  osDelay(pdMS_TO_TICKS(2));
	  }
  /* USER CODE END StartTriggerTask */
}

/* MPU Configuration */

void MPU_Config(void)
{
  MPU_Region_InitTypeDef MPU_InitStruct = {0};

  /* Disables the MPU */
  HAL_MPU_Disable();
  /** Initializes and configures the Region and the memory to be protected
  */
  MPU_InitStruct.Enable = MPU_REGION_ENABLE;
  MPU_InitStruct.Number = MPU_REGION_NUMBER0;
  MPU_InitStruct.BaseAddress = 0x30040000;
  MPU_InitStruct.Size = MPU_REGION_SIZE_32KB;
  MPU_InitStruct.SubRegionDisable = 0x0;
  MPU_InitStruct.TypeExtField = MPU_TEX_LEVEL1;
  MPU_InitStruct.AccessPermission = MPU_REGION_FULL_ACCESS;
  MPU_InitStruct.DisableExec = MPU_INSTRUCTION_ACCESS_DISABLE;
  MPU_InitStruct.IsShareable = MPU_ACCESS_NOT_SHAREABLE;
  MPU_InitStruct.IsCacheable = MPU_ACCESS_NOT_CACHEABLE;
  MPU_InitStruct.IsBufferable = MPU_ACCESS_NOT_BUFFERABLE;

  HAL_MPU_ConfigRegion(&MPU_InitStruct);
  /** Initializes and configures the Region and the memory to be protected
  */
  MPU_InitStruct.Number = MPU_REGION_NUMBER1;
  MPU_InitStruct.Size = MPU_REGION_SIZE_256B;
  MPU_InitStruct.TypeExtField = MPU_TEX_LEVEL0;
  MPU_InitStruct.IsShareable = MPU_ACCESS_SHAREABLE;
  MPU_InitStruct.IsBufferable = MPU_ACCESS_BUFFERABLE;

  HAL_MPU_ConfigRegion(&MPU_InitStruct);
  /* Enables the MPU */
  HAL_MPU_Enable(MPU_PRIVILEGED_DEFAULT);

}
void HAL_TIM_PeriodElapsedCallback(TIM_HandleTypeDef *htim)
{
  if (htim->Instance == TIM1) {
    HAL_IncTick();
  }
}

void Error_Handler(void)
{
  __disable_irq();
  while (1)
  {
  }
}

/************************ (C) COPYRIGHT STMicroelectronics *****END OF FILE****/
